# Musca_B1 register map
Vendor: ARM Ltd.; Series: ARMv8-M Mainline; File version: 1.0
ARM 32-bit v8-M Mainline based device
CPU: CM33 r0p2, little endian, MPU, FPU, 4 interrupt priority bits, 8 SAU regions
Registers are 32-bit, read-write, reset 0x0 unless marked. A register's access mark holds for its fields unless they carry their own. Offsets are from the block's base; lines under a group give offsets from that group; [hi:lo] are bit positions; {n}, {i} and the like mark numbered series; 'fields as' and 'values as' point back to an identical list; <NAME> marks a mode.

## Memory map
0x40000000 TIMER0 size 0x10
0x40001000 TIMER1 size 0x10
0x40002000 DUALTIMER size 0x3C
0x40020000 SYSINFO size 0x1000 — System Information
0x4002F000 S32KTIMER size 0x10
0x40080000 NSPCTRL size 0x1000 — Non-secure Privilege Control Block
0x40081000 WATCHDOG size 0xC04 — Non-secure Watchdog Timer
0x40105000 UART0 size 0x4C
0x40106000 UART1 size 0x4C
0x40107000 PWM size 0x20 — PWM_IP6512
0x4010A000 SPI0 size 0xFC
0x4010C000 GPTIMER size 0x20 — General-Purpose Timer
0x41000000 GPIO0 size 0x3C — General-purpose I/O 0
0x42800000 QSPIFCTRL size 0xB0 — QSPI Flash Controller
0x50000000 TIMER0_Secure size 0x10
0x50001000 TIMER1_Secure size 0x10
0x50002000 DUALTIMER_Secure size 0x3C
0x50010000 iCache size 0x1000 — Cache
0x50020000 SYSINFO_Secure size 0x1000 — System Information (Secure)
0x50021000 SystemControl size 0x1000
0x5002E000 S32KWATCHDOG size 0xC04 — S32K Watchdog (Secure)
0x5002F000 S32KTIMER_Secure size 0x10
0x50080000 SPCTRL size 0x1000 — Secure Privilege Control Block
0x50081000 WATCHDOG_Secure size 0xC04
0x50083000 SRAM0MPC size 0x1000 — Memory Protection Controller 0
0x50084000 SRAM1MPC size 0x1000 — SRAM 1 Memory Protection Controller
0x50085000 SRAM2MPC size 0x1000 — SRAM 2 Memory Protection Controller
0x50086000 SRAM3MPC size 0x1000 — SRAM 3 Memory Protection Controller
0x50105000 UART0_Secure size 0x4C
0x50106000 UART1_Secure size 0x4C
0x5010A000 SPI0_Secure size 0xFC
0x5010B000 SCC size 0x1000 — Serial Communication Controller
0x5010C000 GPTIMER_Secure size 0x20 — General-Purpose Timer (Secure)
0x51000000 GPIO0_Secure size 0x3C — General-purpose I/O 0 (Secure)
0x52000000 QSPI_MPC size 0x1000 — QSPI Flash Memory Protection Controller
0x52100000 CODE_SRAM_MPC size 0x1000 — Code SRAM Memory Protection Controller
0x52200000 EFLASH0_MPC size 0x1000 — EFlash0 Memory Protection Controller
0x52300000 EFLASH1_MPC size 0x1000 — EFlash1 Memory Protection Controller
0x52800000 QSPIFCTRL_Secure size 0xB0 — QSPI Flash Controller (Secure)
0xE000EDD0 SAU size 0x20 — Security Attribution Unit

## Interrupts
1 NONSEC_WATCHDOG_IRQ (WATCHDOG) — Non-Secure Watchdog Interrupt
2 S32KTIMER — Timer 1
3 TIMER0
4 TIMER1
5 DUALTIMER
9 MPC (SRAM0MPC) — MPC Combined
33 GPTIMERINTR (GPTIMER) — General-Purpose Timer interrupt
37 SPIINTR0 (SPI0) — SPI0 interrupt
38 QSPIINTR (QSPIFCTRL) — QSPI interrupt
39 UARTRXINTR0 (UART0) — UART0 receive FIFO interrupt
45 UARTRXINTR1 (UART1) — UART1 receive FIFO interrupt
68 GPIO0 — GPIO 0 combined
70 PWMINT0 (PWM) — PWM0 interrupt

## SYSINFO — System Information
Base 0x40020000
Same registers: SYSINFO_Secure 0x50020000
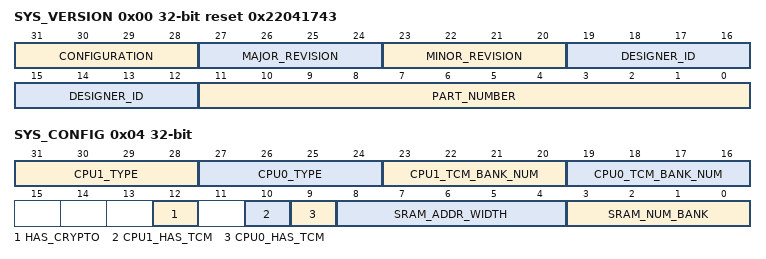
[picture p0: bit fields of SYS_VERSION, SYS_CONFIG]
0x00 SYS_VERSION ro reset 0x22041743 — System Version Register
  [31:28] CONFIGURATION — CONFIGURATION for SSE-200 r2: 0x2
  [27:24] MAJOR_REVISION
  [23:20] MINOR_REVISION
  [19:12] DESIGNER_ID — Arm Product with designer code 0x41
  [11:0] PART_NUMBER — Part Number for the SSE-200
0x04 SYS_CONFIG ro — System Hardware Configuration register
  [31:28] CPU1_TYPE — CPU 1 Core Type
    0=Not Exist (Does Not Exist); 2=CM33 (Cortex-M33 Core)
  [27:24] CPU0_TYPE — CPU 0 Core Type
    0=Not Exist (Does Not Exist); 2=CM33 (Cortex-M33 Core)
  [23:20] CPU1_TCM_BANK_NUM — Number of SRAM banks
    3=Four (4 SRAM Banks); 2=Three (3 SRAM Banks); 1=Two (2 SRAM Banks); 0=Otherwise
  [19:16] CPU0_TCM_BANK_NUM — The SRAM Bank that maps CPU0 Data TCM
  [12] HAS_CRYPTO — Whether CryptoCell Included:
    0=No (CryptoCell Not Included); 1=Yes (CryptoCell Included)
  [10] CPU1_HAS_TCM — CPU 1 has Data TCM:
    0=No (CPU 1 does not have Data TCM); 1=Yes (CPU 1 has Data TCM)
  [9] CPU0_HAS_TCM — CPU 0 has Data TCM:
    0=No (CPU 0 does not have Data TCM); 1=Yes (CPU 0 has Data TCM)
  [8:4] SRAM_ADDR_WIDTH — SRAM Bank Address Width
  [3:0] SRAM_NUM_BANK — SRAM Number of Banks
0xFD0 PIDR4 ro reset 0x4 — Peripheral ID 4
0xFE0 PIDR0 ro reset 0x58 — Peripheral ID 0
0xFE4 PIDR1 ro reset 0xB8 — Peripheral ID 1
0xFE8 PIDR2 ro reset 0xB — Peripheral ID 2
0xFEC PIDR3 ro — Peripheral ID 3
0xFF0 CIDR0 ro reset 0xD — Component ID 0
0xFF4 CIDR1 ro reset 0xF0 — Component ID 1
0xFF8 CIDR2 ro reset 0x5 — Component ID 2
0xFFC CIDR3 ro reset 0xB1 — Component ID 3

## Licence text in the file
ARM Limited (ARM) is supplying this software for use with Cortex-M processor based microcontroller, but can be equally used for other suitable processor architectures. This file can be freely distributed. Modifications to this file shall be clearly marked. . THIS SOFTWARE IS PROVIDED "AS IS". NO WARRANTIES, WHETHER EXPRESS, IMPLIED. OR STATUTORY, INCLUDING, BUT NOT LIMITED TO, IMPLIED WARRANTIES OF. MERCHANTABILITY AND FITNESS FOR A PARTICULAR PURPOSE APPLY TO THIS SOFTWARE. ARM SHALL NOT, IN ANY CIRCUMSTANCES, BE LIABLE FOR SPECIAL, INCIDENTAL, OR. CONSEQUENTIAL DAMAGES, FOR ANY REASON WHATSOEVER.

## Notices in the file
Copyright (C) 2012-2019 ARM Limited. All rights reserved.
Purpose: System Viewer Description (SVD) Example (Schema Version 1.1)
This is a description of a none-existent and incomplete device
for demonstration purposes only.
Redistribution and use in source and binary forms, with or without
modification, are permitted provided that the following conditions are met:
- Redistributions of source code must retain the above copyright
notice, this list of conditions and the following disclaimer.
- Redistributions in binary form must reproduce the above copyright
notice, this list of conditions and the following disclaimer in the
documentation and/or other materials provided with the distribution.
- Neither the name of ARM nor the names of its contributors may be used
to endorse or promote products derived from this software without
specific prior written permission.
THIS SOFTWARE IS PROVIDED BY THE COPYRIGHT HOLDERS AND CONTRIBUTORS "AS IS"
AND ANY EXPRESS OR IMPLIED WARRANTIES, INCLUDING, BUT NOT LIMITED TO, THE
ARE DISCLAIMED. IN NO EVENT SHALL COPYRIGHT HOLDERS AND CONTRIBUTORS BE
LIABLE FOR ANY DIRECT, INDIRECT, INCIDENTAL, SPECIAL, EXEMPLARY, OR
CONSEQUENTIAL DAMAGES (INCLUDING, BUT NOT LIMITED TO, PROCUREMENT OF
SUBSTITUTE GOODS OR SERVICES; LOSS OF USE, DATA, OR PROFITS; OR BUSINESS
INTERRUPTION) HOWEVER CAUSED AND ON ANY THEORY OF LIABILITY, WHETHER IN
CONTRACT, STRICT LIABILITY, OR TORT (INCLUDING NEGLIGENCE OR OTHERWISE)
ARISING IN ANY WAY OUT OF THE USE OF THIS SOFTWARE, EVEN IF ADVISED OF THE
POSSIBILITY OF SUCH DAMAGE.
